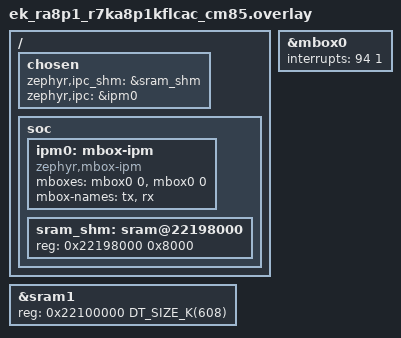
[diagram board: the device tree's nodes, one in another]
/*
 * Copyright (c) 2025 Renesas Electronics Corporation
 * SPDX-License-Identifier: Apache-2.0
 */

/ {
	chosen {
		/*
		 * shared memory reserved for the inter-processor communication
		 */

		zephyr,ipc_shm = &sram_shm;
		zephyr,ipc = &ipm0;
	};

	soc {
		ipm0: mbox-ipm {
			compatible = "zephyr,mbox-ipm";
			mboxes = <&mbox0 0>, <&mbox0 0>;
			mbox-names = "tx", "rx";
			status = "okay";
		};

		/* Define shared memory regions for IPC */
		sram_shm: sram@22198000 {
			reg = <0x22198000 0x8000>;
		};
	};
};

/* Redefine sram size for CPU1 */
&sram1 {
	reg = <0x22100000 DT_SIZE_K(608)>;
};

&mbox0 {
	interrupts = <94 1>;
	status = "okay";
};
